# Cortex_M52 register map
Vendor: Arm Ltd.; Series: ARMv8.1-M Mainline; File version: 1.0.0
CPU: other r0p0, little endian, MPU, FPU, double-precision FPU, DSP, 8 interrupt priority bits
Registers are 32-bit, read-write, reset 0x0 unless marked. A register's access mark holds for its fields unless they carry their own. Offsets are from the block's base; [hi:lo] are bit positions.

## ICB — Implementation Control Block (ARMv8.1-M): interrupt controller type, the implementation-defined Auxiliary Control Register and coprocessor power control.
Base 0xE000E000
Same registers: ICB_NS 0xE002E000
0x04 ICTR ro — Interrupt Controller Type Register: how many interrupt lines the NVIC supports, in groups of 32. Read-only.
  [3:0] INTLINESNUM — Number of interrupt lines in groups of 32: the NVIC supports up to 32 x (INTLINESNUM+1) interrupts.
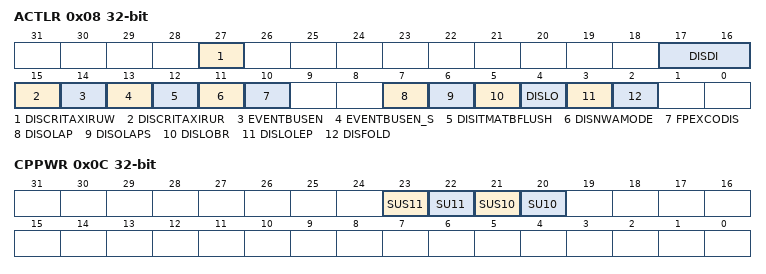
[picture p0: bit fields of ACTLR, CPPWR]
0x08 ACTLR — Auxiliary Control Register: implementation-defined controls that disable individual micro-architectural features of the core. Usually left at reset.
  [27] DISCRITAXIRUW — 1 = disable critical-word-first AXI read-under-write.
  [17:16] DISDI — Disable dual issue for the instruction classes selected by these bits (see the core TRM).
  [15] DISCRITAXIRUR — 1 = disable critical-word-first AXI read-under-read.
  [14] EVENTBUSEN — 1 = enable the event bus (exports PMU events on the EVENT interface).
  [13] EVENTBUSEN_S — 1 = enable the Secure event bus (PMU/DWT event export for Secure events).
  [12] DISITMATBFLUSH — 1 = disable the ITM and DWT ATB flush handshake.
  [11] DISNWAMODE — 1 = disable no-write-allocate mode of the data cache (write misses then allocate).
  [10] FPEXCODIS — 1 = disable the FPU exception outputs; the cumulative FPSCR flags still update.
  [7] DISOLAP — 1 = disable overlapping (beat-wise interleaving) of MVE vector instructions with following instructions.
  [6] DISOLAPS — Disable overlapping of scalar instructions with MVE (vector) instructions in the pipeline (Secure-controlled variant).
  [5] DISLOBR — 1 = disable low-overhead-loop branch prediction.
  [4] DISLO — 1 = disable the low-overhead-loop (LO) cache; loops fall back to ordinary branch handling.
  [3] DISLOLEP — 1 = disable low-overhead-loop end prediction (the LE branch is predicted only from the LO loop cache).
  [2] DISFOLD — 1 = disable instruction folding.
0x0C CPPWR — Coprocessor Power Control Register (ARMv8.1-M): per-coprocessor 'state unknown' permissions that let the implementation power-gate the FPU/MVE and custom coprocessors.
  [23] SUS11 — SU11 Secure only.
  [22] SU11 — State Unknown for CP11 (FPU/MVE), must equal SU10.
  [21] SUS10 — SU10 Secure only: 1 = SU10 can only be changed from Secure state.
  [20] SU10 — State Unknown for CP10 (FPU/MVE): 1 = the implementation may power down the unit and its register state may become unknown; software must then re-initialise it.

## SysTick — 24-bit system timer that counts down from LOAD to 0 on the processor or reference clock and can raise the SysTick exception; the usual RTOS tick source. Banked per security state on ARMv8-M with the Security Extension.
Base 0xE000E010
Same registers: SysTick_NS 0xE002E010
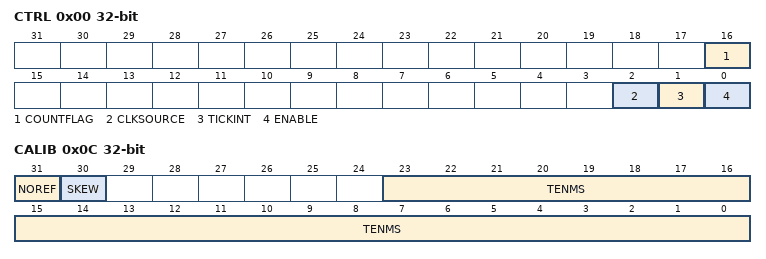
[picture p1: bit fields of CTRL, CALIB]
0x00 CTRL — SysTick Control and Status Register: enable, interrupt enable, clock source and the sticky count-to-zero flag.
  [16] COUNTFLAG ro — Reads 1 if the counter reached 0 since the last read of this register. Cleared by reading CTRL or writing VAL.
  [2] CLKSOURCE — Clock source: 0 = external reference clock (implementation defined, e.g. HCLK/8), 1 = processor clock.
    0=External reference clock (implementation defined); 1=Processor clock
  [1] TICKINT — 1 = counting down to 0 sets the SysTick exception pending; 0 = poll COUNTFLAG instead.
  [0] ENABLE — Counter enable: 1 = SysTick counts down from LOAD to 0 and reloads.
0x04 LOAD — SysTick Reload Value Register: value loaded into VAL when the counter reaches 0. A period of N clocks needs RELOAD = N-1.
  [23:0] RELOAD — Value loaded into VAL when the counter reaches 0. A period of N clocks needs RELOAD = N-1; 0 is legal but the counter then never fires.
0x08 VAL — SysTick Current Value Register: the current count. Any write clears it to 0 and clears CTRL.COUNTFLAG; the next reload comes from LOAD.
  [23:0] CURRENT — Current counter value. Any write clears the field to 0 and clears CTRL.COUNTFLAG.
0x0C CALIB ro — SysTick Calibration Register: implementation-defined reload value for a 10 ms tick and whether a reference clock exists.
  [31] NOREF — 1 = no separate reference clock: CLKSOURCE reads 1 and cannot be cleared.
  [30] SKEW — 1 = TENMS is not exact (a 10 ms tick cannot be produced exactly).
  [23:0] TENMS — Reload value for a 10 ms period with the reference clock, or 0 if unknown. Implementation defined.
